# ATtiny828 device description
Architecture: AVR8; Family: tinyAVR
Programming and debug interfaces: ISP, HVPP, debugWIRE
Registers are 8-bit, access not given, no defined reset value unless marked. A register's access mark holds for its fields unless they carry their own. Offsets are from the block's base; lines under a group give offsets from that group; [hi:lo] are bit positions; {n}, {i} and the like mark numbered series; 'fields as' and 'values as' point back to an identical list; <NAME> marks a mode.

## Ordering variants
ATtiny828R-AUR, ATtiny828-AU, ATtiny828-AUR, ATtiny828R-AU: TQFP32, up to 20 MHz, -40 to 85 C, 1.62 to 5.5 V
ATtiny828-MU, ATtiny828-MUR: VQFN32, up to 20 MHz, -40 to 85 C, 1.62 to 5.5 V

## Memory
prog space: start 0x0000 size 0x2000, little endian
  0x0000 FLASH size 0x2000 flash, rw, executable, page 0x40
  0x1f00 BOOT_SECTION_1 size 0x0100 flash, rw, executable, page 0x40
  0x1e00 BOOT_SECTION_2 size 0x0200 flash, rw, executable, page 0x40
  0x1c00 BOOT_SECTION_3 size 0x0400 flash, rw, executable, page 0x40
  0x1800 BOOT_SECTION_4 size 0x0800 flash, rw, executable, page 0x40
signatures space: start 0 size 3, little endian
  0 SIGNATURES size 3 signatures, ro
fuses space: start 0 size 0x0003, little endian
  0 FUSES size 0x0003 fuses, rw
lockbits space: start 0 size 0x0001, little endian
  0 LOCKBITS size 0x0001 lockbits, rw
data space: start 0x0000 size 0x0300, little endian
  0x0000 REGISTERS size 0x0020 regs
  0x0020 MAPPED_IO size 0x00e0 io
  0x0100 IRAM size 0x0200 ram
eeprom space: start 0x0000 size 0x0100, little endian
  0x0000 EEPROM size 0x0100 eeprom, rw, page 0x04
io space: start 0x00 size 0x40, little endian
osccal space: start 0 size 2, little endian
  0 OSCCAL size 2 osccal, ro

## Peripheral instances (address, pins/pin function, parameters)
SPI at 0x00 — Serial Peripheral Interface
PORTA at 0x00 — I/O Port
PORTB at 0x00 — I/O Port
PORTC at 0x00 — I/O Port
PORTD at 0x00 — I/O Port
CPU at 0x00 — CPU Registers
  parameters: CORE_VERSION=V2, NEW_INSTRUCTIONS=lpm rd,z+
TC0 at 0x00 — Timer/Counter, 8-bit
TC1 at 0x00 — Timer/Counter, 16-bit
TOCPM at 0x00 — Timer/Counter Output Compare Pin
ADC at 0x00 — Analog-to-Digital Converter
AC at 0x00 — Analog Comparator
EXINT at 0x00 — External Interrupts
WDT at 0x00 — Watchdog Timer
EEPROM at 0x00
TWI at 0x00 — Two Wire Serial Interface
USART at 0x00
FUSE at 0 in fuses — Fuses
LOCKBIT at 0 in lockbits — Lockbits

## Interrupts
0 RESET — External Pin, Power-on Reset, Brown-out Reset and Watchdog Reset
1 INT0 — External Interrupt Request 0
2 INT1 — External Interrupt Request 1
3 PCINT0 — Pin Change Interrupt Request 0
4 PCINT1 — Pin Change Interrupt Request 1
5 PCINT2 — Pin Change Interrupt Request 2
6 PCINT3 — Pin Change Interrupt Request 3
7 WDT — Watchdog Time-out Interrupt
8 TIMER1_CAPT — Timer/Counter1 Capture Event
9 TIMER1_COMPA — Timer/Counter1 Compare Match A
10 TIMER1_COMPB — Timer/Counter1 Compare Match B
11 TIMER1_OVF — Timer/Counter1 Overflow
12 TIMER0_COMPA — Timer/Counter0 Compare Match A
13 TIMER0_COMPB — Timer/Counter0 Compare Match B
14 TIMER0_OVF — Timer/Counter0 Overflow
15 SPI_STC — SPI Serial Transfer Complete
16 USART_START
17 USART_RX — USART Rx Complete
18 USART_UDRE — USART, Data Register Empty
19 USART_TX — USART Tx Complete
20 ADC — ADC Conversion Complete
21 EE_READY — EEPROM Ready
22 ANALOG_COMP — Analog Comparator
23 TWI_SLAVE — Two-wire Serial Interface
24 SPM_Ready — Store Program Memory Read
25 QTRIP — Touch Sensing

## Properties
SIGNATURES: JTAGID=0x9314, SIGNATURE0=0x1e, SIGNATURE1=0x93, SIGNATURE2=0x14
OCD: OCD_REVISION=1, OCD_DATAREG=0x31, PROGBASE=0x0000

## FUSE — Fuses
Instances: FUSE 0 in fuses
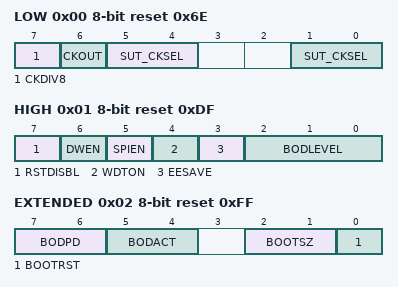
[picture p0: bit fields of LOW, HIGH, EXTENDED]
0x00 LOW reset 0x6E
  [7] CKDIV8 — Divide clock by 8 internally
  [6] CKOUT — Clock output on PORTB0
  [5:4,1:0] SUT_CKSEL — Select Clock Source
    0=EXTCLK_6CK_14CK_0MS (Ext. Clock; Start-up time PWRDWN/RESET: 6 + 14 CK + 0 ms); 1=EXTCLK_6CK_14CK_0MS (Ext. Clock; Start-up time PWRDWN/RESET: 6 + 14 CK + 0 ms); 16=EXTCLK_6CK_14CK_4MS1 (Ext. Clock; Start-up time PWRDWN/RESET: 6 + 14 CK + 4.1 ms); 17=EXTCLK_6CK_14CK_4MS1 (Ext. Clock; Start-up time PWRDWN/RESET: 6 + 14 CK + 4.1 ms); 32=EXTCLK_6CK_14CK_65MS (Ext. Clock; Start-up time PWRDWN/RESET: 6 + 14 CK + 65 ms); 48=EXTCLK_6CK_14CK_65MS (Ext. Clock; Start-up time PWRDWN/RESET: 6 + 14 CK + 65 ms); 33=EXTCLK_6CK_14CK_65MS (Ext. Clock; Start-up time PWRDWN/RESET: 6 + 14 CK + 65 ms); 49=EXTCLK_6CK_14CK_65MS (Ext. Clock; Start-up time PWRDWN/RESET: 6 + 14 CK + 65 ms); 2=INTRCOSC_8MHZ_6CK_14CK_0MS (Int. RC Osc. 8 MHz; Start-up time PWRDWN/RESET: 6 + 14 CK + 0 ms); 18=INTRCOSC_8MHZ_6CK_14CK_4MS1 (Int. RC Osc. 8 MHz; Start-up time PWRDWN/RESET: 6 + 14 CK + 4.1 ms); 34=INTRCOSC_8MHZ_6CK_14CK_65MS (Int. RC Osc. 8 MHz; Start-up time PWRDWN/RESET: 6 + 14 CK + 65 ms); 50=INTRCOSC_8MHZ_6CK_14CK_65MS (Int. RC Osc. 8 MHz; Start-up time PWRDWN/RESET: 6 + 14 CK + 65 ms); 3=INTULPOSC_32KHZ_6CK_14CK_0MS (Int. ULP Osc. 32kHz; Start-up time PWRDWN/RESET: 6 + 14 CK + 0 ms); 19=INTULPOSC_32KHZ_6CK_14CK_4MS1 (Int. ULP Osc. 32kHz; Start-up time PWRDWN/RESET: 6 + 14 CK + 4.1 ms); 35=INTULPOSC_32KHZ_6CK_14CK_65MS (Int. ULP Osc. 32kHz; Start-up time PWRDWN/RESET: 6 + 14 CK + 65 ms); 51=INTULPOSC_32KHZ_6CK_14CK_65MS (Int. ULP Osc. 32kHz; Start-up time PWRDWN/RESET: 6 + 14 CK + 65 ms)
0x01 HIGH reset 0xDF
  [7] RSTDISBL — Reset Disabled (Enable PC6 as i/o pin)]
  [6] DWEN — Debug Wire enable
  [5] SPIEN — Serial program downloading (SPI) enabled
  [4] WDTON — Watch-dog Timer always on
  [3] EESAVE — Preserve EEPROM through the Chip Erase cycle
  [2:0] BODLEVEL — Brown-out Detector trigger level
    7=DISABLED (Brown-out detection disabled); 4=4V3 (Brown-out detection at VCC=4.3 V); 5=2V7 (Brown-out detection at VCC=2.7 V); 6=1V8 (Brown-out detection at VCC=1.8 V)
0x02 EXTENDED reset 0xFF
  [7:6] BODPD — BOD mode of operation when the device is in sleep mode
    1=BOD_SAMPLED (Sampled); 2=BOD_ENABLED (Enabled); 3=BOD_DISABLED (Disabled)
  [5:4] BODACT — BOD mode of operation when the device is active or idle
    values as BODPD
  [2:1] BOOTSZ — Select boot size
    3=128W_0F80 (Boot Flash size=128 words Boot address=$0F80); 2=256W_0F00 (Boot Flash size=256 words Boot address=$0F00); 1=512W_0E00 (Boot Flash size=512 words Boot address=$0E00); 0=1024W_0C00 (Boot Flash size=1024 words Boot address=$0C00)
  [0] BOOTRST — Boot Reset vector Enabled
